# FRAM_1 register map
Vendor: Texas Instruments
Peripheral module from a debugger description file (folder msp430).
Registers are 16-bit, read-write, reset 0x0 unless marked. A register's access mark holds for its fields unless they carry their own. Offsets are as the file gives them; lines under a group give offsets from that group; [hi:lo] are bit positions; {n}, {i} and the like mark numbered series; 'fields as' and 'values as' point back to an identical list; <NAME> marks a mode.

## FRAM
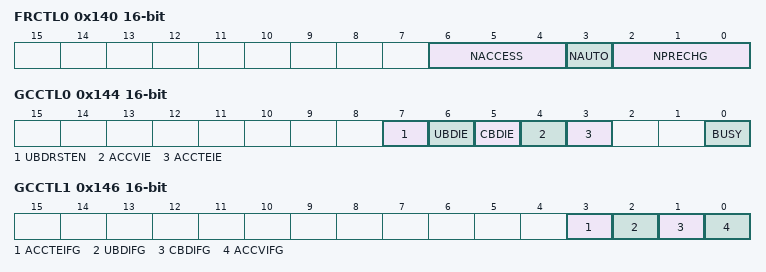
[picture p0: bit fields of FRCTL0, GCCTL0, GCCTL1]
0x140 FRCTL0 — FRAM Controller Control 0
  [6:4] NACCESS — FRAM Wait state Generator Access Time control Bit: 0
    {v}=FRAM Wait state Generator Access Time control: {v} (v=0..7)
  [3] NAUTO — FRAM Disables the wait state generator
  [2:0] NPRECHG — FRAM Wait state Generator Precharge Time control Bit: 0
    {v}=FRAM Wait state Generator Precharge Time control: {v} (v=0..7)
0x144 GCCTL0 — General Control 0
  [7] UBDRSTEN — Enable Power Up Clear on uncorrectable bit error
  [6] UBDIE — Enable NMI event if uncorrectable bit error detected
  [5] CBDIE — Enable NMI event if correctable bit error detected
  [4] ACCVIE — Enable NMI event if Access Violation occurs
  [3] ACCTEIE — Enable NMI event if Access time error occurs
  [0] BUSY — FRAM is currently busy programming
0x146 GCCTL1 — General Control 1
  [3] ACCTEIFG — Access time error flag
  [2] UBDIFG — FRAM uncorrectable bit error flag
  [1] CBDIFG — FRAM correctable bit error flag
  [0] ACCVIFG — Access Violation Interrupt Flag
